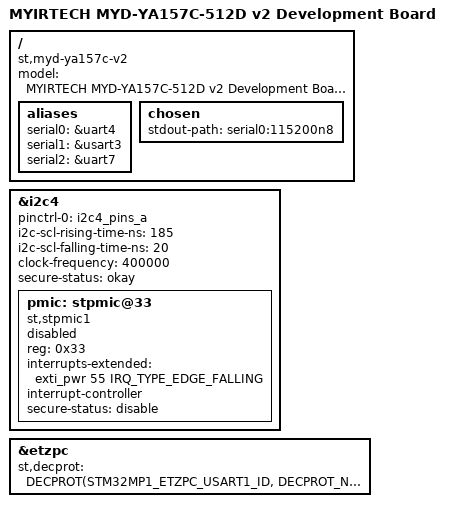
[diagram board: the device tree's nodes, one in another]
// SPDX-License-Identifier: (GPL-2.0+ OR BSD-3-Clause)


/dts-v1/;

#include "stm32mp157.dtsi"
#include "stm32mp15xa.dtsi"
#include "stm32mp15-pinctrl.dtsi"
#include "stm32mp15xxac-pinctrl.dtsi"
#include <dt-bindings/soc/st,stm32-etzpc.h>
#include "stm32mp15xx-ya157c.dtsi"

/ {
	model = "MYIRTECH MYD-YA157C-512D v2 Development Board";
	compatible = "st,myd-ya157c-v2", "st,stm32mp157";
	
	aliases {
		serial0 = &uart4;
		serial1 = &usart3;
		serial2 = &uart7;
	};

	chosen {
		stdout-path = "serial0:115200n8";
	};

};

&i2c4 {
	pinctrl-names = "default";
	pinctrl-0 = <&i2c4_pins_a>;
	i2c-scl-rising-time-ns = <185>;
	i2c-scl-falling-time-ns = <20>;
	clock-frequency = <400000>;
	status = "okay";
	secure-status = "okay";

	pmic: stpmic@33 {
		compatible = "st,stpmic1";
		reg = <0x33>;
		interrupts-extended = <&exti_pwr 55 IRQ_TYPE_EDGE_FALLING>;
		interrupt-controller;
		#interrupt-cells = <2>;
		status = "disable";
		secure-status = "disable";

		
	};
};
&etzpc {
	st,decprot = <
		DECPROT(STM32MP1_ETZPC_USART1_ID, DECPROT_NS_RW, DECPROT_UNLOCK)
		DECPROT(STM32MP1_ETZPC_SPI6_ID, DECPROT_NS_RW, DECPROT_UNLOCK)
		DECPROT(STM32MP1_ETZPC_I2C4_ID, DECPROT_NS_RW, DECPROT_UNLOCK)
		DECPROT(STM32MP1_ETZPC_I2C6_ID, DECPROT_NS_RW, DECPROT_UNLOCK)
		DECPROT(STM32MP1_ETZPC_RNG1_ID, DECPROT_NS_RW, DECPROT_UNLOCK)
		DECPROT(STM32MP1_ETZPC_HASH1_ID, DECPROT_NS_RW, DECPROT_UNLOCK)
		DECPROT(STM32MP1_ETZPC_DDRCTRL_ID, DECPROT_S_RW, DECPROT_LOCK)
		DECPROT(STM32MP1_ETZPC_DDRPHYC_ID, DECPROT_S_RW, DECPROT_LOCK)
		DECPROT(STM32MP1_ETZPC_STGENC_ID, DECPROT_S_RW, DECPROT_LOCK)
		DECPROT(STM32MP1_ETZPC_BKPSRAM_ID, DECPROT_S_RW, DECPROT_LOCK)
		DECPROT(STM32MP1_ETZPC_IWDG1_ID, DECPROT_S_RW, DECPROT_LOCK)
	>;
};


